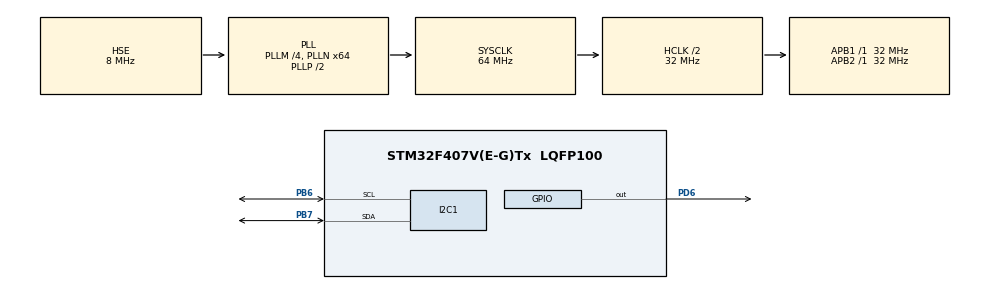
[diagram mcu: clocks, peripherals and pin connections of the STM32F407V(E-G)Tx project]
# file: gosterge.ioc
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Dma.I2C1_RX.0.Direction=DMA_PERIPH_TO_MEMORY
Dma.I2C1_RX.0.FIFOMode=DMA_FIFOMODE_DISABLE
Dma.I2C1_RX.0.Instance=DMA1_Stream0
Dma.I2C1_RX.0.MemDataAlignment=DMA_MDATAALIGN_BYTE
Dma.I2C1_RX.0.MemInc=DMA_MINC_DISABLE
Dma.I2C1_RX.0.Mode=DMA_NORMAL
Dma.I2C1_RX.0.PeriphDataAlignment=DMA_PDATAALIGN_BYTE
Dma.I2C1_RX.0.PeriphInc=DMA_PINC_DISABLE
Dma.I2C1_RX.0.Priority=DMA_PRIORITY_MEDIUM
Dma.I2C1_TX.1.Direction=DMA_MEMORY_TO_PERIPH
Dma.I2C1_TX.1.FIFOMode=DMA_FIFOMODE_DISABLE
Dma.I2C1_TX.1.Instance=DMA1_Stream6
Dma.I2C1_TX.1.MemDataAlignment=DMA_MDATAALIGN_BYTE
Dma.I2C1_TX.1.MemInc=DMA_MINC_DISABLE
Dma.I2C1_TX.1.Mode=DMA_NORMAL
Dma.I2C1_TX.1.PeriphDataAlignment=DMA_PDATAALIGN_BYTE
Dma.I2C1_TX.1.PeriphInc=DMA_PINC_DISABLE
Dma.I2C1_TX.1.Priority=DMA_PRIORITY_LOW
Dma.Request0=I2C1_RX
Dma.Request1=I2C1_TX
Mcu.Family=STM32F4
Mcu.Name=STM32F407V(E-G)Tx
Mcu.Package=LQFP100
NVIC.DMA1_Stream0_IRQn=true\:0\:0\:false\:false\:true\:false\:true\:true
NVIC.DMA1_Stream6_IRQn=true\:0\:0\:false\:false\:true\:false\:true\:true
NVIC.PriorityGroup=NVIC_PRIORITYGROUP_4
PB6.Mode=I2C
PB6.Signal=I2C1_SCL
PB7.Mode=I2C
PB7.Signal=I2C1_SDA
PD6.Signal=GPIO_Output
PH0-OSC_IN.Mode=HSE-External-Oscillator
PH0-OSC_IN.Signal=RCC_OSC_IN
PH1-OSC_OUT.Mode=HSE-External-Oscillator
PH1-OSC_OUT.Signal=RCC_OSC_OUT
ProjectManager.HeapSize=0x200
ProjectManager.StackSize=0x400
ProjectManager.TargetToolchain=STM32CubeIDE
RCC.48MHZClocksFreq_Value=32000000
RCC.AHBCLKDivider=RCC_SYSCLK_DIV2
RCC.AHBFreq_Value=32000000
RCC.APB1Freq_Value=32000000
RCC.APB1TimFreq_Value=32000000
RCC.APB2Freq_Value=32000000
RCC.APB2TimFreq_Value=32000000
RCC.CortexFreq_Value=32000000
RCC.HCLKFreq_Value=32000000
RCC.HSE_VALUE=8000000
RCC.HSI_VALUE=16000000
RCC.LSE_VALUE=32768
RCC.PLLM=4
RCC.PLLN=64
RCC.PLLSourceVirtual=RCC_PLLSOURCE_HSE
RCC.SYSCLKFreq_VALUE=64000000
RCC.SYSCLKSource=RCC_SYSCLKSOURCE_PLLCLK
RCC.VCOOutputFreq_Value=128000000
TIM1.Prescaler=31
VP_TIM1_VS_ClockSourceINT.Mode=Internal
board=custom

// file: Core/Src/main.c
/* USER CODE BEGIN Header */
/**
  ******************************************************************************
  * @file           : main.c
  * @brief          : Main program body
  ******************************************************************************
  * @attention
  *
  * Copyright (c) 2025 STMicroelectronics.
  * All rights reserved.
  *
  * This software is licensed under terms that can be found in the LICENSE file
  * in the root directory of this software component.
  * If no LICENSE file comes with this software, it is provided AS-IS.
  *
  ******************************************************************************
  */
/* USER CODE END Header */
#include "main.h"

/* USER CODE BEGIN Includes */
#include <stdio.h>
#include "mpu6050.h"
#include "dht11.h"

/* USER CODE END Includes */

/* USER CODE BEGIN PD */
#define DHT11_PORT 		GPIOD
#define DHT11_PORT_PIN 	GPIO_PIN_6

/* USER CODE END PD */

I2C_HandleTypeDef hi2c1;
DMA_HandleTypeDef hdma_i2c1_rx;
DMA_HandleTypeDef hdma_i2c1_tx;

TIM_HandleTypeDef htim1;

/* USER CODE BEGIN PV */
uint8_t who_am_i;

/* USER CODE END PV */

void SystemClock_Config(void);
static void MX_GPIO_Init(void);
static void MX_DMA_Init(void);
static void MX_I2C1_Init(void);
static void MX_TIM1_Init(void);

int main(void)
{

  /* MCU Configuration--------------------------------------------------------*/

  /* Reset of all peripherals, Initializes the Flash interface and the Systick. */
  HAL_Init();

  /* Configure the system clock */
  SystemClock_Config();

  /* Initialize all configured peripherals */
  MX_GPIO_Init();
  MX_DMA_Init();
  MX_I2C1_Init();
  MX_TIM1_Init();
  /* USER CODE BEGIN 2 */
  MpuData mpu;
  Dht11 dht;
  who_am_i = WhoamI_Control(&hi2c1);
  if( who_am_i == 0x68 ){
	  Mpu_Conf(&hi2c1);
  }

  /* USER CODE END 2 */

  /* Infinite loop */
  while (1)
  {

    /* USER CODE BEGIN 3 */
	  if( who_am_i == 0x68 ){
		  mpu = Mpu_Oku(&hi2c1);
	  }
	  dht = DHT11_Oku(&htim1, DHT11_PORT, GPIO_PIN_6);
	  HAL_Delay(500);

  }
  /* USER CODE END 3 */
}

void SystemClock_Config(void)
{
  RCC_OscInitTypeDef RCC_OscInitStruct = {0};
  RCC_ClkInitTypeDef RCC_ClkInitStruct = {0};

  /** Configure the main internal regulator output voltage
  */
  __HAL_RCC_PWR_CLK_ENABLE();
  __HAL_PWR_VOLTAGESCALING_CONFIG(PWR_REGULATOR_VOLTAGE_SCALE1);

  /** Initializes the RCC Oscillators according to the specified parameters
  * in the RCC_OscInitTypeDef structure.
  */
  RCC_OscInitStruct.OscillatorType = RCC_OSCILLATORTYPE_HSE;
  RCC_OscInitStruct.HSEState = RCC_HSE_ON;
  RCC_OscInitStruct.PLL.PLLState = RCC_PLL_ON;
  RCC_OscInitStruct.PLL.PLLSource = RCC_PLLSOURCE_HSE;
  RCC_OscInitStruct.PLL.PLLM = 4;
  RCC_OscInitStruct.PLL.PLLN = 64;
  RCC_OscInitStruct.PLL.PLLP = RCC_PLLP_DIV2;
  RCC_OscInitStruct.PLL.PLLQ = 4;
  if (HAL_RCC_OscConfig(&RCC_OscInitStruct) != HAL_OK)
  {
    Error_Handler();
  }

  /** Initializes the CPU, AHB and APB buses clocks
  */
  RCC_ClkInitStruct.ClockType = RCC_CLOCKTYPE_HCLK|RCC_CLOCKTYPE_SYSCLK
                              |RCC_CLOCKTYPE_PCLK1|RCC_CLOCKTYPE_PCLK2;
  RCC_ClkInitStruct.SYSCLKSource = RCC_SYSCLKSOURCE_PLLCLK;
  RCC_ClkInitStruct.AHBCLKDivider = RCC_SYSCLK_DIV2;
  RCC_ClkInitStruct.APB1CLKDivider = RCC_HCLK_DIV1;
  RCC_ClkInitStruct.APB2CLKDivider = RCC_HCLK_DIV1;

  if (HAL_RCC_ClockConfig(&RCC_ClkInitStruct, FLASH_LATENCY_1) != HAL_OK)
  {
    Error_Handler();
  }
}

static void MX_I2C1_Init(void)
{

  hi2c1.Instance = I2C1;
  hi2c1.Init.ClockSpeed = 100000;
  hi2c1.Init.DutyCycle = I2C_DUTYCYCLE_2;
  hi2c1.Init.OwnAddress1 = 0;
  hi2c1.Init.AddressingMode = I2C_ADDRESSINGMODE_7BIT;
  hi2c1.Init.DualAddressMode = I2C_DUALADDRESS_DISABLE;
  hi2c1.Init.OwnAddress2 = 0;
  hi2c1.Init.GeneralCallMode = I2C_GENERALCALL_DISABLE;
  hi2c1.Init.NoStretchMode = I2C_NOSTRETCH_DISABLE;
  if (HAL_I2C_Init(&hi2c1) != HAL_OK)
  {
    Error_Handler();
  }

}

static void MX_TIM1_Init(void)
{

  TIM_ClockConfigTypeDef sClockSourceConfig = {0};
  TIM_MasterConfigTypeDef sMasterConfig = {0};

  htim1.Instance = TIM1;
  htim1.Init.Prescaler = 31;
  htim1.Init.CounterMode = TIM_COUNTERMODE_UP;
  htim1.Init.Period = 65535;
  htim1.Init.ClockDivision = TIM_CLOCKDIVISION_DIV1;
  htim1.Init.RepetitionCounter = 0;
  htim1.Init.AutoReloadPreload = TIM_AUTORELOAD_PRELOAD_DISABLE;
  if (HAL_TIM_Base_Init(&htim1) != HAL_OK)
  {
    Error_Handler();
  }
  sClockSourceConfig.ClockSource = TIM_CLOCKSOURCE_INTERNAL;
  if (HAL_TIM_ConfigClockSource(&htim1, &sClockSourceConfig) != HAL_OK)
  {
    Error_Handler();
  }
  sMasterConfig.MasterOutputTrigger = TIM_TRGO_RESET;
  sMasterConfig.MasterSlaveMode = TIM_MASTERSLAVEMODE_DISABLE;
  if (HAL_TIMEx_MasterConfigSynchronization(&htim1, &sMasterConfig) != HAL_OK)
  {
    Error_Handler();
  }

}

static void MX_DMA_Init(void)
{

  /* DMA controller clock enable */
  __HAL_RCC_DMA1_CLK_ENABLE();

  /* DMA interrupt init */
  /* DMA1_Stream0_IRQn interrupt configuration */
  HAL_NVIC_SetPriority(DMA1_Stream0_IRQn, 0, 0);
  HAL_NVIC_EnableIRQ(DMA1_Stream0_IRQn);
  /* DMA1_Stream6_IRQn interrupt configuration */
  HAL_NVIC_SetPriority(DMA1_Stream6_IRQn, 0, 0);
  HAL_NVIC_EnableIRQ(DMA1_Stream6_IRQn);

}

static void MX_GPIO_Init(void)
{
  GPIO_InitTypeDef GPIO_InitStruct = {0};

  /* GPIO Ports Clock Enable */
  __HAL_RCC_GPIOH_CLK_ENABLE();
  __HAL_RCC_GPIOD_CLK_ENABLE();
  __HAL_RCC_GPIOB_CLK_ENABLE();

  /*Configure GPIO pin Output Level */
  HAL_GPIO_WritePin(GPIOD, GPIO_PIN_6, GPIO_PIN_RESET);

  /*Configure GPIO pin : PD6 */
  GPIO_InitStruct.Pin = GPIO_PIN_6;
  GPIO_InitStruct.Mode = GPIO_MODE_OUTPUT_PP;
  GPIO_InitStruct.Pull = GPIO_NOPULL;
  GPIO_InitStruct.Speed = GPIO_SPEED_FREQ_LOW;
  HAL_GPIO_Init(GPIOD, &GPIO_InitStruct);

}

/* USER CODE BEGIN 4 */
void HAL_I2C_MasterRxCpltCallback(I2C_HandleTypeDef *I2cHandle)
{
/* ########### */
	//err = 2;
}

int _write(int file, char *ptr, int len)
{
  (void)file;
  int DataIdx;

  for (DataIdx = 0; DataIdx < len; DataIdx++)
  {
    ITM_SendChar(*ptr++);
  }
  return len;
}

/* USER CODE END 4 */

void Error_Handler(void)
{
  /* USER CODE BEGIN Error_Handler_Debug */
	//err = 1;
  /* User can add his own implementation to report the HAL error return state */
  __disable_irq();
  while (1)
  {
  }
  /* USER CODE END Error_Handler_Debug */
}
